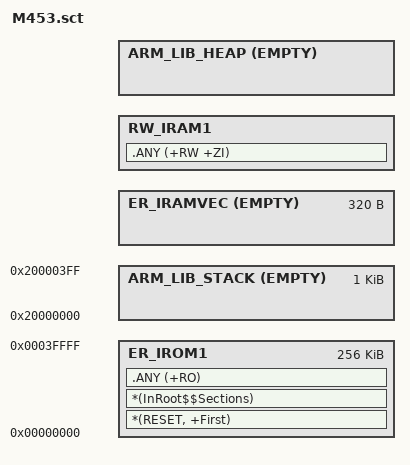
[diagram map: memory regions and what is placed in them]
#! armcc -E

#if !defined(MBED_APP_START)
  #define MBED_APP_START            0x00000000
#endif

#if !defined(MBED_APP_SIZE)
  #define MBED_APP_SIZE             0x00040000
#endif

#if !defined(MBED_RAM_START)
  #define MBED_RAM_START            0x20000000
#endif

#if !defined(MBED_RAM_SIZE)
  #define MBED_RAM_SIZE             0x00008000
#endif


#if !defined(MBED_BOOT_STACK_SIZE)
  #define MBED_BOOT_STACK_SIZE      0x400
#endif

#define VECTOR_SIZE                 (4*(16 + 64))

LR_IROM1  MBED_APP_START  MBED_APP_SIZE  {
  ER_IROM1  MBED_APP_START  MBED_APP_SIZE  {  ; load address = execution address
   *(RESET, +First)
   *(InRoot$$Sections)
   .ANY (+RO)
  }

  ARM_LIB_STACK  MBED_RAM_START  EMPTY  MBED_BOOT_STACK_SIZE  {
  }

  /* VTOR[TBLOFF] alignment requires:
   *
   * 1. Minumum 32-word
   * 2. Rounding up to the next power of two of table size
   */
  ER_IRAMVEC  AlignExpr(+0, 512)  EMPTY  VECTOR_SIZE  {  ; Reserve for vectors
  }

  RW_IRAM1  AlignExpr(+0, 16)  {  ; 16 byte-aligned
   .ANY (+RW +ZI)
  }

  ARM_LIB_HEAP AlignExpr(+0, 16)  EMPTY  (MBED_RAM_START + MBED_RAM_SIZE - AlignExpr(ImageLimit(RW_IRAM1), 16))  {
  }
}
ScatterAssert(LoadLimit(LR_IROM1) <= (MBED_APP_START + MBED_APP_SIZE))    ; 256 KB APROM
ScatterAssert(ImageLimit(ARM_LIB_HEAP) <= (MBED_RAM_START + MBED_RAM_SIZE))   ; 32 KB SRAM

